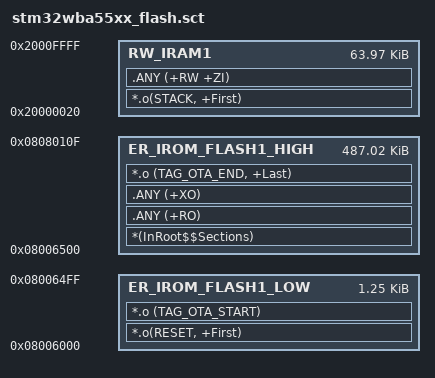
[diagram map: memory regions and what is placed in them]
; *************************************************************
; *** Scatter-Loading Description File                      ***
; *************************************************************
LR_IROM_FLASH1 0x08006000 0x500 {
  ER_IROM_FLASH1_LOW 0x08006000 0x500 {
    *.o(RESET, +First)
    *.o (TAG_OTA_START)
  }

  RW_IRAM1 0x20000020 0x0FFE0 {
    *.o(STACK, +First)
    .ANY (+RW +ZI)
  }

}

LR_IROM_FLASH2 0x08006500 0x79C10{
  ER_IROM_FLASH1_HIGH 0x08006500  0x79C10 {
  *(InRoot$$Sections)
  .ANY (+RO)
  .ANY (+XO)
  *.o (TAG_OTA_END, +Last)	
  }
 }
;LR_IROM_DWN 0x08080000 0x7A000 {
;  LR_IROM_DWN 0x08080000 0x7A000 {
;  }
;}
;LR_IROM_NVM 0x0807FA000 0x4000 {
;  ER_IROM_NVM 0x0807FA000 0x4000 {
;  }
;}
;LR_IROM_DATA 0x080FE000 0x2000 {
;  LR_IROM_DATA 0x080FE000 0x2000 {
;  }
;}
